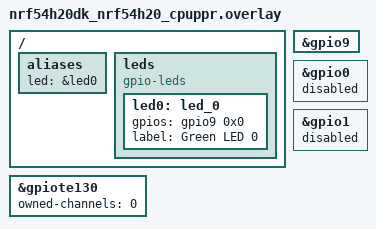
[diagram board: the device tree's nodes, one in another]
/ {
	aliases {
		led = &led0;
	};

	leds {
		compatible = "gpio-leds";

		led0: led_0 {
			gpios = <&gpio9 0x0 0x0>;
			label = "Green LED 0";
		};
	};
};

&gpio9 {
	status = "okay";
};

&gpio0 {
	status = "disabled";
};

&gpio1 {
	status = "disabled";
};

&gpiote130 {
	status = "okay";
	owned-channels = <0>;
};
